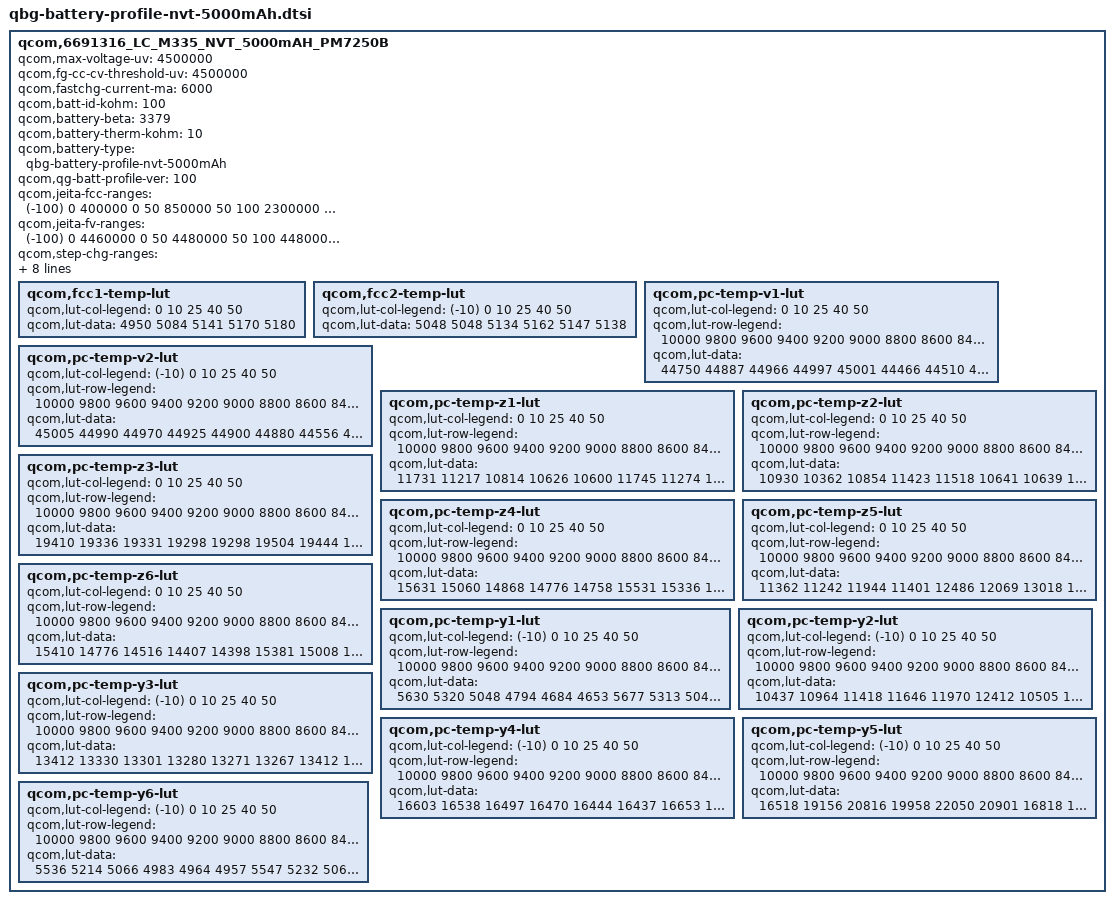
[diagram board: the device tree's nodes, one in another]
qcom,6691316_LC_M335_NVT_5000mAH_PM7250B {
	qcom,max-voltage-uv = <4500000>;
	qcom,fg-cc-cv-threshold-uv = <4500000>;
	qcom,fastchg-current-ma = <6000>;
	qcom,batt-id-kohm = <100>;
	qcom,battery-beta = <3379>;
	qcom,battery-therm-kohm = <10>;
	qcom,battery-type = "qbg-battery-profile-nvt-5000mAh";
	qcom,qg-batt-profile-ver = <100>;
	qcom,jeita-fcc-ranges = <(-100) 0 400000 0 50 850000 50 100 2300000 100 150 3700000 150 350 6000000 350 480 6000000 480 560 2300000>;
	qcom,jeita-fv-ranges = <(-100) 0 4460000 0 50 4480000 50 100 4480000 100 150 4480000 150 350 4450000 350 480 4450000 480 560 4100000>;
	qcom,step-chg-ranges = <3600000 4250000 6000000 4250001 4480000 5400000 4480001 4500000 3920000>;
	qcom,vbat-avg-based-step-chg;
	qcom,taper-fcc;
	qcom,jeita-soft-thresholds = <9556 3725>;
	qcom,jeita-hard-thresholds = <17365 2967>;
	qcom,jeita-soft-hys-thresholds = <8799 4060>;
	qcom,jeita-soft-fcc-ua = <5400000 2500000>;
	qcom,jeita-soft-fv-uv = <4480000 4100000>;

	qcom,fcc1-temp-lut {
		qcom,lut-col-legend = <0 10 25 40 50>;
		qcom,lut-data = <4950 5084 5141 5170 5180>;
	};

	qcom,fcc2-temp-lut {
		qcom,lut-col-legend = <(-10) 0 10 25 40 50>;
		qcom,lut-data = <5048 5048 5134 5162 5147 5138>;
	};

	qcom,pc-temp-v1-lut {
		qcom,lut-col-legend = <0 10 25 40 50>;
		qcom,lut-row-legend = <10000 9800 9600 9400 9200 9000 8800 8600 8400 8200 8000 7800 7600 7400 7200 7000 6800 6600 6400 6200 6000 5800 5600 5400 5200 5000 4800 4600 4400 4200 4000 3800 3600 3400 3200 3000 2800 2600 2400 2200 2000 1800 1600 1400 1200 1000 900 800 700 600 500 400 300 200 100 0>;
		qcom,lut-data = <44750 44887 44966 44997 45001
		                44466 44510 44557 44573 44578
		                44188 44224 44267 44265 44274
		                43987 44039 44035 44029 44035
		                43806 43842 43827 43811 43814
		                43594 43613 43600 43584 43584
		                43381 43406 43391 43368 43372
		                43172 43205 43195 43175 43182
		                42966 43000 42992 42974 42985
		                42751 42792 42785 42769 42783
		                42544 42584 42577 42563 42578
		                42336 42372 42363 42352 42366
		                42132 42165 42153 42145 42160
		                41930 41955 41938 41929 41942
		                41736 41749 41732 41719 41730
		                41549 41547 41526 41511 41521
		                41365 41355 41326 41307 41315
		                41187 41174 41138 41114 41120
		                41010 41002 40960 40931 40933
		                40831 40836 40800 40776 40777
		                40655 40666 40642 40629 40635
		                40476 40488 40470 40461 40473
		                40325 40316 40283 40272 40288
		                40186 40160 40098 40082 40094
		                40018 40030 39963 39942 39951
		                39799 39866 39879 39863 39870
		                39520 39662 39737 39742 39751
		                39135 39297 39314 39299 39306
		                38673 38806 38809 38824 38820
		                38223 38306 38341 38335 38333
		                37741 37790 37769 37794 37805
		                37244 37312 37284 37275 37277
		                36781 36813 36801 36786 36792
		                36347 36285 36342 36276 36255
		                35897 35766 35754 35694 35637
		                35390 35260 35216 35169 35142
		                34854 34674 34667 34606 34598
		                34377 34191 34175 34083 34063
		                33936 33765 33707 33641 33618
		                33532 33381 33321 33203 33226
		                33138 32996 32907 32873 32876
		                32790 32628 32606 32578 32578
		                32468 32384 32318 32315 32306
		                32150 32142 32117 32087 32073
		                31877 31857 31829 31807 31806
		                31644 31556 31578 31573 31569
		                31380 31245 31249 31244 31252
		                31113 30983 30974 30963 30978
		                30883 30736 30743 30722 30728
		                30694 30459 30469 30460 30468
		                30416 29943 30061 30129 30161
		                30019 29268 29440 29506 29546
		                29402 28518 28683 28828 28958
		                29114 27756 28171 28418 28447
		                28402 27310 27452 26971 27330
		                26968 27529 24719 27433 26552
		                26947 21442 23160 23556 23026
		                22888 23711 22398 22712 23241>;
	};

	qcom,pc-temp-v2-lut {
		qcom,lut-col-legend = <(-10) 0 10 25 40 50>;
		qcom,lut-row-legend = <10000 9800 9600 9400 9200 9000 8800 8600 8400 8200 8000 7800 7600 7400 7200 7000 6800 6600 6400 6200 6000 5800 5600 5400 5200 5000 4800 4600 4400 4200 4000 3800 3600 3400 3200 3000 2800 2600 2400 2200 2000 1800 1600 1400 1200 1000 900 800 700 600 500 400 300 200 100 0>;
		qcom,lut-data = <45005 44990 44970 44925 44900 44880
		                44556 44590 44590 44564 44521 44498
		                44197 44272 44291 44294 44216 44183
		                43906 43989 44014 44026 43931 43895
		                43655 43753 43778 43782 43685 43648
		                43442 43549 43573 43556 43466 43431
		                43246 43368 43390 43346 43263 43230
		                43078 43199 43219 43165 43094 43066
		                42931 43041 43057 43002 42936 42910
		                42784 42881 42892 42838 42775 42752
		                42641 42731 42739 42683 42623 42602
		                42496 42582 42587 42527 42473 42454
		                42353 42432 42435 42368 42320 42305
		                42209 42272 42274 42199 42157 42146
		                42066 42106 42108 42022 41984 41977
		                41922 41936 41936 41838 41804 41801
		                41773 41762 41759 41662 41632 41628
		                41595 41559 41544 41436 41403 41398
		                41382 41328 41279 41166 41129 41123
		                41175 41140 41100 40997 40968 40970
		                41016 40997 40968 40877 40858 40869
		                40869 40856 40837 40783 40781 40788
		                40782 40770 40755 40708 40724 40720
		                40715 40703 40692 40634 40676 40659
		                40635 40624 40616 40542 40620 40601
		                40531 40517 40513 40426 40512 40508
		                40466 40462 40462 40316 40371 40383
		                40397 40403 40401 40220 40225 40245
		                40316 40334 40334 40131 40097 40108
		                40206 40238 40242 40014 40004 39984
		                40037 40079 40092 39748 39839 39886
		                39880 39913 39930 39516 39711 39779
		                39765 39768 39767 39379 39567 39608
		                39588 39571 39537 39257 39388 39391
		                39347 39313 39264 39122 39193 39148
		                39087 39056 39006 38946 38958 38874
		                38793 38766 38718 38730 38705 38582
		                38497 38477 38432 38488 38454 38332
		                38260 38243 38202 38229 38199 38134
		                38092 38079 38045 37968 37940 37983
		                38037 38030 37993 37726 37695 37838
		                37949 37959 37936 37490 37452 37659
		                37832 37857 37844 37301 37210 37432
		                37627 37683 37678 37087 36961 37155
		                37344 37430 37428 36842 36739 36870
		                37045 37136 37139 36602 36542 36630
		                36782 36850 36844 36385 36370 36425
		                36558 36604 36585 36184 36204 36229
		                36354 36385 36348 35975 36034 36036
		                36160 36182 36129 35743 35845 35849
		                35973 35997 35940 35459 35601 35664
		                35804 35837 35781 35091 35251 35404
		                35583 35613 35550 34715 34851 35066
		                35289 35313 35243 34349 34430 34649
		                34888 34918 34842 33955 34014 34199
		                34473 34503 34422 33519 33594 33710
		                33980 34007 33924 32965 33023 33127
		                33310 33358 33265 32385 32478 32582
		                32712 32741 32634 31851 31944 32098
		                32231 32240 32155 31056 31165 31312
		                31492 31501 31459 30299 30375 30582
		                30813 30893 30848 29662 29765 30027
		                30258 30261 30191 28946 29168 29412
		                29678 29656 29588 27684 28255 28473
		                28689 28678 28651 26978 27460 27963
		                28197 28202 28145 25704 26798 27040
		                27269 27269 27123 24715 25933 26435
		                26815 26863 26836 23595 25435 25011
		                25875 26055 25936 21852 23826 24452
		                24665 24680 24725 19287 21648 22120
		                22503 22675 22720 16972 19442 19565
		                19794 20086 20287 15010 17588 17772
		                17871 17560 17772 12738 12192 12322
		                12468 11898 11879 12817 12100 12221
		                10423 12028 9322 12632 12051 9243
		                8693 10569 9210 12632 12051 9243>;
	};

	qcom,pc-temp-z1-lut {
		qcom,lut-col-legend = <0 10 25 40 50>;
		qcom,lut-row-legend = <10000 9800 9600 9400 9200 9000 8800 8600 8400 8200 8000 7800 7600 7400 7200 7000 6800 6600 6400 6200 6000 5800 5600 5400 5200 5000 4800 4600 4400 4200 4000 3800 3600 3400 3200 3000 2800 2600 2400 2200 2000 1800 1600 1400 1200 1000 900 800 700 600 500 400 300 200 100 0>;
		qcom,lut-data = <11731 11217 10814 10626 10600
		                11745 11274 10840 10661 10632
		                11754 11258 10839 10654 10629
		                11757 11236 10829 10649 10628
		                11759 11232 10820 10647 10627
		                11759 11232 10813 10647 10628
		                11750 11231 10808 10648 10630
		                11736 11219 10805 10649 10633
		                11712 11203 10804 10651 10636
		                11678 11197 10803 10653 10640
		                11646 11193 10806 10656 10644
		                11635 11191 10809 10660 10649
		                11631 11193 10814 10664 10653
		                11632 11195 10819 10669 10658
		                11633 11200 10825 10674 10662
		                11633 11207 10832 10679 10667
		                11632 11213 10840 10684 10672
		                11633 11218 10845 10689 10677
		                11638 11224 10850 10695 10682
		                11652 11229 10857 10700 10687
		                11669 11237 10864 10706 10692
		                11682 11242 10871 10711 10696
		                11699 11247 10875 10715 10700
		                11713 11259 10878 10719 10704
		                11722 11278 10889 10723 10708
		                11731 11290 10906 10730 10713
		                11737 11296 10917 10737 10719
		                11743 11302 10925 10744 10724
		                11749 11307 10933 10751 10729
		                11753 11312 10940 10756 10734
		                11756 11317 10946 10761 10739
		                11756 11322 10954 10766 10743
		                11755 11324 10962 10772 10747
		                11754 11326 10970 10777 10751
		                11753 11330 10977 10782 10755
		                11760 11338 10982 10787 10759
		                11774 11344 10986 10791 10763
		                11779 11344 10989 10794 10767
		                11778 11344 10995 10798 10769
		                11777 11345 11000 10802 10772
		                11777 11347 11003 10805 10775
		                11777 11347 11005 10807 10777
		                11777 11347 11005 10809 10779
		                11777 11347 11005 10810 10781
		                11777 11348 11006 10811 10782
		                11777 11348 11006 10812 10782
		                11777 11348 11006 10812 10782>;
	};

	qcom,pc-temp-z2-lut {
		qcom,lut-col-legend = <0 10 25 40 50>;
		qcom,lut-row-legend = <10000 9800 9600 9400 9200 9000 8800 8600 8400 8200 8000 7800 7600 7400 7200 7000 6800 6600 6400 6200 6000 5800 5600 5400 5200 5000 4800 4600 4400 4200 4000 3800 3600 3400 3200 3000 2800 2600 2400 2200 2000 1800 1600 1400 1200 1000 900 800 700 600 500 400 300 200 100 0>;
		qcom,lut-data = <10930 10362 10854 11423 11518
		                10641 10639 11004 11116 11389
		                10593 10714 11094 11417 11396
		                10587 10761 11042 11407 11501
		                10573 10757 10994 11360 11608
		                10556 10698 10950 11322 11590
		                10525 10659 10922 11290 11553
		                10495 10638 10916 11269 11525
		                10463 10624 10922 11275 11502
		                10423 10617 10925 11286 11480
		                10397 10614 10924 11284 11469
		                10381 10616 10917 11273 11463
		                10372 10618 10906 11266 11458
		                10367 10629 10897 11262 11461
		                10365 10647 10893 11260 11473
		                10362 10662 10894 11260 11487
		                10359 10677 10897 11262 11494
		                10358 10689 10904 11265 11495
		                10360 10697 10914 11269 11494
		                10364 10703 10925 11276 11493
		                10369 10694 10933 11280 11488
		                10372 10661 10937 11279 11481
		                10373 10648 10946 11280 11479
		                10371 10662 10983 11299 11493
		                10369 10676 11026 11338 11528
		                10367 10674 11021 11356 11539
		                10366 10666 10986 11345 11523
		                10366 10665 10965 11335 11501
		                10367 10668 10963 11335 11495
		                10370 10675 10967 11337 11496
		                10374 10687 10968 11338 11497
		                10377 10703 10970 11339 11498
		                10379 10709 10975 11343 11502
		                10383 10713 10987 11351 11510
		                10389 10716 10994 11359 11517
		                10395 10722 10997 11366 11523
		                10400 10734 11001 11373 11530
		                10405 10745 11011 11381 11541
		                10409 10750 11029 11395 11561
		                10412 10750 11039 11415 11576
		                10415 10750 11041 11421 11570
		                10419 10753 11043 11423 11559
		                10423 10757 11046 11426 11552
		                10427 10763 11051 11433 11550
		                10430 10768 11057 11437 11548
		                10431 10772 11061 11436 11548
		                10431 10772 11061 11436 11548>;
	};

	qcom,pc-temp-z3-lut {
		qcom,lut-col-legend = <0 10 25 40 50>;
		qcom,lut-row-legend = <10000 9800 9600 9400 9200 9000 8800 8600 8400 8200 8000 7800 7600 7400 7200 7000 6800 6600 6400 6200 6000 5800 5600 5400 5200 5000 4800 4600 4400 4200 4000 3800 3600 3400 3200 3000 2800 2600 2400 2200 2000 1800 1600 1400 1200 1000 900 800 700 600 500 400 300 200 100 0>;
		qcom,lut-data = <19410 19336 19331 19298 19298
		                19504 19444 19370 19314 19289
		                19547 19486 19438 19372 19352
		                19580 19498 19444 19380 19354
		                19604 19508 19447 19383 19356
		                19621 19516 19448 19387 19359
		                19632 19518 19448 19380 19356
		                19636 19520 19444 19376 19352
		                19636 19515 19439 19373 19349
		                19634 19508 19424 19369 19345
		                19628 19500 19414 19366 19342
		                19618 19488 19408 19361 19337
		                19600 19473 19399 19352 19332
		                19580 19458 19391 19345 19328
		                19566 19450 19389 19344 19326
		                19561 19444 19389 19343 19325
		                19559 19439 19389 19342 19323
		                19555 19435 19387 19338 19319
		                19551 19431 19385 19333 19315
		                19547 19429 19384 19332 19315
		                19542 19427 19384 19331 19314
		                19539 19425 19384 19331 19314
		                19536 19423 19383 19331 19314
		                19528 19420 19382 19332 19316
		                19518 19418 19382 19334 19319
		                19513 19417 19383 19336 19322
		                19511 19415 19385 19339 19325
		                19508 19411 19386 19342 19329
		                19501 19406 19386 19343 19330
		                19492 19402 19385 19342 19329
		                19482 19398 19384 19340 19326
		                19475 19396 19382 19337 19322
		                19470 19394 19379 19333 19318
		                19468 19393 19377 19331 19315
		                19466 19392 19375 19332 19317
		                19462 19391 19374 19333 19321
		                19458 19390 19373 19334 19324
		                19455 19389 19372 19334 19326
		                19453 19388 19370 19334 19327
		                19451 19387 19369 19333 19327
		                19449 19386 19368 19332 19325
		                19448 19385 19367 19331 19323
		                19446 19384 19366 19330 19321
		                19444 19383 19365 19330 19321
		                19442 19382 19364 19329 19321
		                19442 19382 19364 19329 19321>;
	};

	qcom,pc-temp-z4-lut {
		qcom,lut-col-legend = <0 10 25 40 50>;
		qcom,lut-row-legend = <10000 9800 9600 9400 9200 9000 8800 8600 8400 8200 8000 7800 7600 7400 7200 7000 6800 6600 6400 6200 6000 5800 5600 5400 5200 5000 4800 4600 4400 4200 4000 3800 3600 3400 3200 3000 2800 2600 2400 2200 2000 1800 1600 1400 1200 1000 900 800 700 600 500 400 300 200 100 0>;
		qcom,lut-data = <15631 15060 14868 14776 14758
		                15531 15336 14850 14720 14682
		                15472 15223 14977 14788 14703
		                15310 15038 14854 14743 14681
		                15113 14872 14790 14712 14665
		                14914 14779 14744 14686 14641
		                14807 14664 14696 14658 14616
		                14633 14646 14637 14618 14597
		                14512 14615 14625 14602 14587
		                14340 14588 14602 14583 14574
		                14149 14455 14567 14564 14560
		                14118 14381 14509 14525 14528
		                14108 14360 14470 14491 14501
		                14100 14353 14443 14462 14476
		                14095 14349 14428 14434 14451
		                14090 14345 14419 14404 14422
		                14088 14342 14412 14376 14397
		                14085 14339 14401 14368 14390
		                14083 14331 14384 14365 14388
		                14081 14321 14367 14364 14386
		                14079 14316 14359 14364 14384
		                14076 14318 14355 14366 14386
		                14074 14321 14351 14367 14388
		                14073 14320 14345 14364 14385
		                14072 14313 14339 14354 14372
		                14072 14307 14334 14346 14357
		                14074 14306 14331 14339 14347
		                14077 14305 14330 14334 14342
		                14079 14303 14329 14332 14340
		                14081 14301 14329 14332 14340
		                14083 14299 14328 14331 14340
		                14084 14297 14328 14331 14340
		                14085 14296 14328 14331 14340
		                14086 14296 14328 14331 14340
		                14087 14296 14328 14331 14340
		                14087 14296 14328 14331 14340
		                14087 14296 14328 14331 14340
		                14087 14296 14328 14331 14340
		                14087 14296 14328 14331 14340
		                14087 14296 14328 14331 14340
		                14087 14296 14328 14331 14340
		                14087 14296 14328 14331 14340
		                14087 14296 14328 14331 14340
		                14087 14296 14328 14331 14340
		                14087 14296 14328 14331 14340>;
	};

	qcom,pc-temp-z5-lut {
		qcom,lut-col-legend = <0 10 25 40 50>;
		qcom,lut-row-legend = <10000 9800 9600 9400 9200 9000 8800 8600 8400 8200 8000 7800 7600 7400 7200 7000 6800 6600 6400 6200 6000 5800 5600 5400 5200 5000 4800 4600 4400 4200 4000 3800 3600 3400 3200 3000 2800 2600 2400 2200 2000 1800 1600 1400 1200 1000 900 800 700 600 500 400 300 200 100 0>;
		qcom,lut-data = <11362 11242 11944 11401 12486
		                12069 13018 13737 14204 14540
		                12627 13930 13904 14168 14599
		                13263 14551 14342 14593 14605
		                13684 14920 14619 14751 14807
		                13816 15306 14721 14850 14889
		                13825 15649 14874 14914 15008
		                13900 15941 15025 14937 15117
		                13933 16212 15142 15083 15321
		                14062 16436 15295 15385 15544
		                14568 16572 15507 15664 15672
		                15271 16533 15783 15824 15776
		                15847 16457 16029 16018 15915
		                16042 16322 16217 16181 16095
		                16124 16112 16289 16200 16180
		                16152 16044 16325 16207 16185
		                16087 16149 16366 16210 16143
		                16010 16349 16366 16221 16083
		                15913 16576 16367 16252 16081
		                15868 16773 16389 16258 16083
		                15847 16906 16522 16290 16083
		                15835 17027 16838 16406 16083
		                15835 17105 17064 16581 16085
		                15838 17136 17136 16725 16091
		                15846 17130 17190 16782 16098
		                15860 17106 17254 16875 16125
		                15874 17068 17328 16927 16156
		                15893 16972 17349 16942 16168
		                15937 16567 17409 16969 16184
		                16004 16061 17188 16675 16184
		                16054 15283 15586 15627 15896
		                15654 14485 14577 14037 13625
		                14339 13883 12103 12041 13573
		                15058 15548 16036 14387 13115
		                12206 12778 13585 15647 14168
		                13636 12649 12641 13373 14224
		                15089 16032 16512 12787 12832
		                13119 15916 18463 16542 12299
		                12612 12952 16429 14563 15625
		                15727 15698 15647 13485 15276
		                13153 12177 12408 14278 12018
		                12561 11250 10975 10825 11661
		                10638 10734 8798 10887 10000
		                11512 10411 11424 8748 10002
		                9234 10660 10355 13638 8847
		                9022 9424 11321 10605 11102
		                8502 7638 9241 9158 10370
		                9020 8641 7281 11821 11633
		                10012 7950 7894 8222 10221
		                10057 10082 10040 10065 8856
		                9316 9315 10182 10070>;
	};

	qcom,pc-temp-z6-lut {
		qcom,lut-col-legend = <0 10 25 40 50>;
		qcom,lut-row-legend = <10000 9800 9600 9400 9200 9000 8800 8600 8400 8200 8000 7800 7600 7400 7200 7000 6800 6600 6400 6200 6000 5800 5600 5400 5200 5000 4800 4600 4400 4200 4000 3800 3600 3400 3200 3000 2800 2600 2400 2200 2000 1800 1600 1400 1200 1000 900 800 700 600 500 400 300 200 100 0>;
		qcom,lut-data = <15410 14776 14516 14407 14398
		                15381 15008 14505 14378 14361
		                15316 15020 14557 14414 14383
		                15188 14928 14526 14399 14373
		                15052 14793 14506 14384 14365
		                14931 14671 14473 14358 14350
		                14827 14596 14448 14336 14332
		                14715 14563 14432 14318 14320
		                14617 14544 14425 14307 14312
		                14512 14528 14419 14299 14306
		                14390 14494 14407 14292 14301
		                14315 14456 14385 14281 14293
		                14313 14450 14377 14272 14286
		                14312 14448 14374 14266 14281
		                14310 14446 14371 14261 14276
		                14307 14443 14367 14255 14272
		                14304 14440 14363 14250 14268
		                14302 14437 14358 14248 14267
		                14301 14432 14351 14248 14267
		                14299 14426 14345 14248 14267
		                14298 14422 14341 14248 14268
		                14297 14420 14338 14250 14269
		                14297 14420 14336 14252 14271
		                14298 14421 14334 14255 14274
		                14301 14424 14332 14258 14277
		                14304 14427 14329 14260 14280
		                14308 14430 14326 14262 14282
		                14310 14432 14323 14263 14283
		                14311 14434 14321 14263 14283
		                14311 14436 14319 14262 14283
		                14311 14437 14317 14261 14283
		                14311 14437 14316 14261 14283
		                14311 14437 14315 14261 14283
		                14311 14437 14314 14261 14283
		                14311 14437 14313 14261 14283
		                14311 14437 14312 14261 14283
		                14311 14437 14311 14261 14283
		                14311 14437 14310 14261 14283
		                14311 14437 14310 14261 14283
		                14311 14437 14310 14261 14283
		                14311 14437 14310 14261 14283
		                14311 14437 14310 14261 14283
		                14311 14437 14310 14261 14283
		                14311 14437 14310 14261 14283
		                14311 14437 14310 14261 14283
		                14311 14437 14310 14261 14283
		                14311 14437 14310 14261 14283>;
	};

	qcom,pc-temp-y1-lut {
		qcom,lut-col-legend = <(-10) 0 10 25 40 50>;
		qcom,lut-row-legend = <10000 9800 9600 9400 9200 9000 8800 8600 8400 8200 8000 7800 7600 7400 7200 7000 6800 6600 6400 6200 6000 5800 5600 5400 5200 5000 4800 4600 4400 4200 4000 3800 3600 3400 3200 3000 2800 2600 2400 2200 2000 1800 1600 1400 1200 1000 900 800 700 600 500 400 300 200 100 0>;
		qcom,lut-data = <5630 5320 5048 4794 4684 4653
		                5677 5313 5048 4797 4684 4655
		                5700 5305 5046 4798 4683 4658
		                5715 5299 5043 4797 4683 4660
		                5724 5295 5040 4796 4683 4662
		                5726 5294 5039 4795 4683 4664
		                5718 5295 5039 4793 4683 4666
		                5706 5298 5038 4791 4683 4668
		                5707 5300 5038 4791 4684 4670
		                5720 5301 5037 4794 4685 4672
		                5733 5303 5037 4795 4687 4673
		                5747 5306 5039 4795 4689 4676
		                5759 5310 5042 4795 4690 4678
		                5746 5320 5041 4796 4692 4680
		                5701 5335 5041 4797 4693 4682
		                5675 5344 5042 4799 4695 4684
		                5697 5347 5046 4802 4698 4686
		                5721 5352 5048 4805 4700 4689
		                5723 5348 5046 4807 4702 4690
		                5721 5325 5042 4809 4703 4691
		                5720 5315 5043 4810 4705 4693
		                5724 5322 5048 4812 4707 4694
		                5728 5330 5052 4814 4709 4695
		                5737 5334 5057 4817 4710 4697
		                5757 5330 5065 4820 4712 4700
		                5765 5328 5066 4823 4714 4701
		                5763 5337 5066 4828 4716 4703
		                5760 5348 5066 4832 4718 4704
		                5758 5359 5068 4835 4720 4705
		                5756 5371 5069 4837 4722 4707
		                5755 5375 5071 4839 4724 4708
		                5755 5372 5075 4842 4726 4709
		                5758 5370 5083 4844 4728 4710
		                5770 5373 5087 4846 4730 4712
		                5782 5381 5086 4847 4731 4713
		                5782 5384 5084 4849 4732 4714
		                5777 5378 5087 4850 4733 4715
		                5771 5370 5092 4852 4734 4715
		                5768 5367 5093 4854 4736 4716
		                5763 5369 5086 4855 4737 4717
		                5758 5373 5081 4856 4738 4718
		                5751 5371 5081 4858 4738 4719
		                5743 5365 5086 4860 4739 4720
		                5739 5365 5093 4862 4740 4721
		                5743 5372 5102 4864 4741 4722
		                5764 5377 5104 4866 4742 4723
		                5784 5380 5103 4867 4742 4723
		                5784 5380 5103 4867 4742 4723>;
	};

	qcom,pc-temp-y2-lut {
		qcom,lut-col-legend = <(-10) 0 10 25 40 50>;
		qcom,lut-row-legend = <10000 9800 9600 9400 9200 9000 8800 8600 8400 8200 8000 7800 7600 7400 7200 7000 6800 6600 6400 6200 6000 5800 5600 5400 5200 5000 4800 4600 4400 4200 4000 3800 3600 3400 3200 3000 2800 2600 2400 2200 2000 1800 1600 1400 1200 1000 900 800 700 600 500 400 300 200 100 0>;
		qcom,lut-data = <10437 10964 11418 11646 11970 12412
		                10505 11029 11388 11647 11985 12403
		                10611 11110 11346 11636 11997 12374
		                10748 11188 11293 11615 11998 12320
		                10891 11245 11242 11592 11990 12251
		                11002 11279 11198 11572 11971 12195
		                11082 11305 11159 11559 11933 12148
		                11149 11325 11124 11548 11882 12105
		                11202 11339 11093 11528 11844 12078
		                11245 11355 11070 11484 11816 12058
		                11284 11397 11054 11418 11795 12032
		                11326 11461 11039 11368 11780 11995
		                11378 11504 11022 11347 11770 11977
		                11442 11523 11007 11350 11758 11997
		                11512 11530 11002 11365 11728 12030
		                11553 11533 11007 11384 11707 12048
		                11482 11437 11009 11403 11814 12071
		                11418 11258 11011 11418 11989 12107
		                11403 11205 11015 11395 12024 12152
		                11402 11193 11027 11364 11989 12178
		                11402 11193 11024 11421 11985 12148
		                11346 11196 10985 11480 12023 12077
		                11207 11208 10954 11442 12007 12050
		                11070 11208 10949 11384 11893 12051
		                10962 11201 10949 11367 11939 12044
		                10864 11196 10955 11357 12081 12019
		                10816 11201 10975 11356 12136 11999
		                10795 11223 11011 11348 12104 12006
		                10783 11215 11032 11325 12055 12057
		                10777 11179 11042 11309 12033 12089
		                10775 11146 11049 11311 12087 12109
		                10774 11131 11060 11317 12154 12156
		                10775 11130 11072 11323 12130 12209
		                10777 11142 11085 11332 11995 12261
		                10781 11152 11101 11342 11936 12268
		                10787 11149 11118 11353 11975 12248
		                10793 11129 11136 11362 12035 12223
		                10800 11106 11153 11367 12066 12194
		                10808 11083 11171 11369 12069 12162
		                10816 11062 11185 11370 12071 12145
		                10824 11043 11192 11375 12073 12134
		                10831 11026 11196 11385 12073 12120
		                10837 11012 11198 11395 12066 12118
		                10843 11000 11200 11403 12061 12118
		                10848 10991 11202 11409 12061 12118
		                10848 10991 11202 11409 12061 12118>;
	};

	qcom,pc-temp-y3-lut {
		qcom,lut-col-legend = <(-10) 0 10 25 40 50>;
		qcom,lut-row-legend = <10000 9800 9600 9400 9200 9000 8800 8600 8400 8200 8000 7800 7600 7400 7200 7000 6800 6600 6400 6200 6000 5800 5600 5400 5200 5000 4800 4600 4400 4200 4000 3800 3600 3400 3200 3000 2800 2600 2400 2200 2000 1800 1600 1400 1200 1000 900 800 700 600 500 400 300 200 100 0>;
		qcom,lut-data = <13412 13330 13301 13280 13271 13267
		                13412 13332 13302 13280 13270 13267
		                13412 13336 13304 13281 13270 13267
		                13413 13339 13306 13281 13270 13267
		                13414 13342 13308 13282 13270 13267
		                13415 13344 13309 13282 13270 13267
		                13416 13344 13309 13283 13270 13267
		                13417 13344 13310 13283 13271 13268
		                13417 13345 13310 13283 13271 13268
		                13416 13346 13310 13283 13271 13268
		                13415 13347 13310 13284 13272 13268
		                13412 13347 13310 13284 13272 13268
		                13408 13347 13310 13285 13272 13269
		                13407 13346 13311 13284 13273 13269
		                13406 13344 13312 13284 13273 13269
		                13405 13343 13312 13284 13273 13269
		                13401 13341 13311 13286 13275 13269
		                13396 13340 13310 13288 13276 13269
		                13390 13339 13309 13289 13276 13270
		                13382 13339 13308 13290 13275 13271
		                13376 13338 13307 13290 13275 13272
		                13370 13332 13305 13289 13277 13273
		                13364 13325 13303 13287 13278 13273
		                13356 13322 13300 13283 13274 13270
		                13345 13320 13298 13280 13270 13267
		                13341 13319 13297 13280 13270 13267
		                13343 13317 13296 13280 13270 13267
		                13346 13316 13296 13280 13269 13267
		                13346 13315 13295 13279 13269 13267
		                13344 13314 13295 13279 13269 13267
		                13345 13312 13295 13279 13270 13267
		                13356 13308 13294 13280 13270 13266
		                13370 13305 13294 13280 13270 13266
		                13384 13306 13294 13280 13270 13266
		                13402 13309 13294 13280 13270 13266
		                13422 13312 13294 13280 13271 13267
		                13450 13316 13293 13280 13271 13267
		                13481 13320 13293 13279 13270 13266
		                13526 13325 13293 13278 13268 13264
		                13577 13331 13294 13278 13268 13264
		                13626 13337 13294 13280 13270 13266
		                13660 13341 13294 13281 13272 13268
		                13693 13344 13295 13282 13272 13268
		                13731 13347 13297 13283 13270 13265
		                13774 13351 13302 13283 13268 13264
		                13821 13361 13309 13285 13270 13266
		                13866 13376 13319 13290 13273 13268
		                13924 13394 13331 13295 13275 13269
		                13924 13394 13331 13295 13275 13269>;
	};

	qcom,pc-temp-y4-lut {
		qcom,lut-col-legend = <(-10) 0 10 25 40 50>;
		qcom,lut-row-legend = <10000 9800 9600 9400 9200 9000 8800 8600 8400 8200 8000 7800 7600 7400 7200 7000 6800 6600 6400 6200 6000 5800 5600 5400 5200 5000 4800 4600 4400 4200 4000 3800 3600 3400 3200 3000 2800 2600 2400 2200 2000 1800 1600 1400 1200 1000 900 800 700 600 500 400 300 200 100 0>;
		qcom,lut-data = <16603 16538 16497 16470 16444 16437
		                16653 16562 16526 16468 16440 16435
		                16736 16602 16556 16464 16436 16432
		                16849 16663 16585 16460 16432 16428
		                16974 16742 16612 16457 16429 16424
		                17072 16816 16632 16456 16427 16422
		                17145 16873 16648 16455 16427 16421
		                17197 16918 16656 16455 16427 16420
		                17194 16941 16658 16457 16428 16420
		                17101 16937 16655 16460 16431 16422
		                17022 16923 16651 16466 16437 16426
		                17037 16915 16655 16474 16445 16430
		                17082 16920 16669 16485 16454 16434
		                17153 16950 16687 16496 16461 16438
		                17244 16997 16704 16504 16464 16440
		                17271 17009 16723 16514 16467 16444
		                17261 16988 16750 16528 16474 16448
		                17229 16953 16770 16543 16484 16451
		                17133 16907 16771 16561 16499 16458
		                16984 16860 16747 16582 16520 16470
		                16817 16785 16703 16590 16533 16482
		                16661 16678 16637 16556 16495 16449
		                16517 16568 16566 16498 16423 16375
		                16394 16453 16495 16464 16408 16358
		                16286 16353 16435 16447 16404 16355
		                16196 16276 16382 16437 16405 16356
		                16134 16220 16330 16424 16412 16366
		                16093 16178 16280 16376 16387 16348
		                16063 16149 16236 16290 16317 16289
		                16042 16129 16204 16229 16250 16215
		                16028 16117 16188 16201 16221 16184
		                16018 16111 16183 16193 16218 16178
		                16005 16111 16180 16192 16220 16180
		                15985 16115 16177 16192 16214 16178
		                15962 16120 16173 16186 16197 16169
		                15936 16125 16170 16175 16167 16148
		                15913 16127 16172 16165 16139 16127
		                15894 16129 16182 16158 16115 16105
		                15878 16132 16195 16155 16101 16092
		                15864 16136 16209 16158 16096 16088
		                15851 16140 16224 16168 16095 16088
		                15839 16145 16240 16182 16099 16089
		                15828 16149 16254 16191 16102 16092
		                15818 16153 16267 16194 16101 16089
		                15809 16158 16278 16194 16096 16082
		                15802 16163 16288 16193 16092 16079
		                15798 16169 16298 16194 16092 16079
		                15798 16169 16298 16194 16092 16079>;
	};

	qcom,pc-temp-y5-lut {
		qcom,lut-col-legend = <(-10) 0 10 25 40 50>;
		qcom,lut-row-legend = <10000 9800 9600 9400 9200 9000 8800 8600 8400 8200 8000 7800 7600 7400 7200 7000 6800 6600 6400 6200 6000 5800 5600 5400 5200 5000 4800 4600 4400 4200 4000 3800 3600 3400 3200 3000 2800 2600 2400 2200 2000 1800 1600 1400 1200 1000 900 800 700 600 500 400 300 200 100 0>;
		qcom,lut-data = <16518 19156 20816 19958 22050 20901
		                16818 19764 21745 21468 22822 21182
		                17174 20430 22379 22318 23272 22321
		                17573 21041 22787 22742 23528 23873
		                18028 21533 22966 22913 23516 25234
		                18497 21745 22957 22780 23280 26101
		                19162 21505 22807 22011 22580 26749
		                19740 21143 22728 21207 21917 28296
		                19790 20907 22848 21019 21805 28614
		                19672 20701 23094 21040 22050 28217
		                19553 20438 22507 20986 21833 27091
		                19327 19757 21192 20567 21017 25510
		                18719 18862 20047 19500 19519 23802
		                18859 18266 19598 17902 17654 21768
		                19682 17668 19055 16421 16626 19967
		                20451 17321 18469 16074 16534 18666
		                21127 17528 17694 16582 17454 17526
		                21407 18222 16268 18436 18633 16576
		                20521 19540 16214 20691 20020 16943
		                18570 22875 18415 24669 22587 19163
		                17426 26193 20987 28251 24320 20842
		                17315 30437 24523 32715 27158 22899
		                17198 33352 28285 36841 29851 25560
		                17191 33453 33082 38462 31521 28594
		                17140 33516 36761 38347 31668 30011
		                17223 33713 37373 37133 31310 30302
		                17338 34035 36433 35396 30921 30014
		                17346 34118 33171 33257 29352 28009
		                17326 34134 30594 30670 27337 25516
		                17360 34138 30591 28444 25519 23535
		                17423 34122 30552 27364 24000 22178
		                17517 34105 30555 27381 23900 22088
		                17682 34105 30661 27559 24411 22652
		                17777 34117 30917 27701 24671 22987
		                17459 34189 31763 27831 24714 23141
		                17094 34232 32819 27985 24771 23245
		                17003 34250 33593 28312 24872 23418
		                16948 34269 34248 28782 25034 23650
		                16903 34192 34775 29184 25243 23894
		                16871 33812 35091 29587 25692 24182
		                16849 33520 35239 29980 26147 24423
		                16846 33518 35321 30416 26395 24506
		                16845 33517 35339 30830 26474 24517
		                16845 33517 35339 30830 26474 24517>;
	};

	qcom,pc-temp-y6-lut {
		qcom,lut-col-legend = <(-10) 0 10 25 40 50>;
		qcom,lut-row-legend = <10000 9800 9600 9400 9200 9000 8800 8600 8400 8200 8000 7800 7600 7400 7200 7000 6800 6600 6400 6200 6000 5800 5600 5400 5200 5000 4800 4600 4400 4200 4000 3800 3600 3400 3200 3000 2800 2600 2400 2200 2000 1800 1600 1400 1200 1000 900 800 700 600 500 400 300 200 100 0>;
		qcom,lut-data = <5536 5214 5066 4983 4964 4957
		                5547 5232 5069 4980 4961 4955
		                5564 5255 5073 4975 4958 4953
		                5587 5280 5077 4970 4954 4951
		                5613 5303 5081 4966 4952 4950
		                5636 5320 5085 4964 4951 4950
		                5656 5331 5089 4963 4951 4949
		                5669 5341 5093 4963 4952 4949
		                5668 5349 5098 4964 4954 4950
		                5648 5356 5104 4968 4957 4951
		                5629 5363 5111 4973 4960 4952
		                5645 5368 5122 4980 4963 4954
		                5705 5371 5142 4989 4967 4955
		                5779 5381 5146 4995 4971 4957
		                5855 5422 5132 4993 4975 4960
		                5913 5459 5107 4974 4978 4961
		                5953 5457 5067 4949 4980 4960
		                5966 5416 5031 4927 4982 4959
		                5946 5393 5043 4908 4975 4962
		                5855 5385 5069 4893 4970 4970
		                5786 5381 5071 4881 4980 4982
		                5744 5387 5057 4882 4997 4993
		                5692 5395 5041 4881 4974 4975
		                5573 5395 5032 4875 4911 4925
		                5471 5393 5021 4862 4887 4912
		                5413 5391 5012 4858 4881 4909
		                5387 5371 5004 4856 4871 4907
		                5381 5320 5000 4856 4868 4907
		                5383 5275 5003 4858 4868 4907
		                5379 5268 5001 4866 4872 4908
		                5361 5309 4999 4883 4875 4910
		                5342 5348 5002 4899 4877 4911
		                5338 5368 5010 4909 4875 4910
		                5336 5379 5019 4916 4875 4909
		                5332 5383 5028 4924 4877 4909
		                5328 5386 5036 4933 4882 4911
		                5326 5388 5044 4942 4892 4915
		                5322 5393 5047 4941 4898 4916
		                5300 5411 5048 4928 4889 4907
		                5290 5436 5053 4919 4879 4897
		                5286 5464 5064 4930 4884 4901
		                5272 5488 5088 4962 4900 4914
		                5220 5505 5105 4971 4907 4921
		                5168 5508 5095 4961 4906 4920
		                5098 5473 5066 4938 4899 4916
		                5033 5420 5035 4923 4898 4917
		                5021 5411 5042 4924 4899 4918
		                5021 5411 5042 4924 4899 4918>;
	};
};
